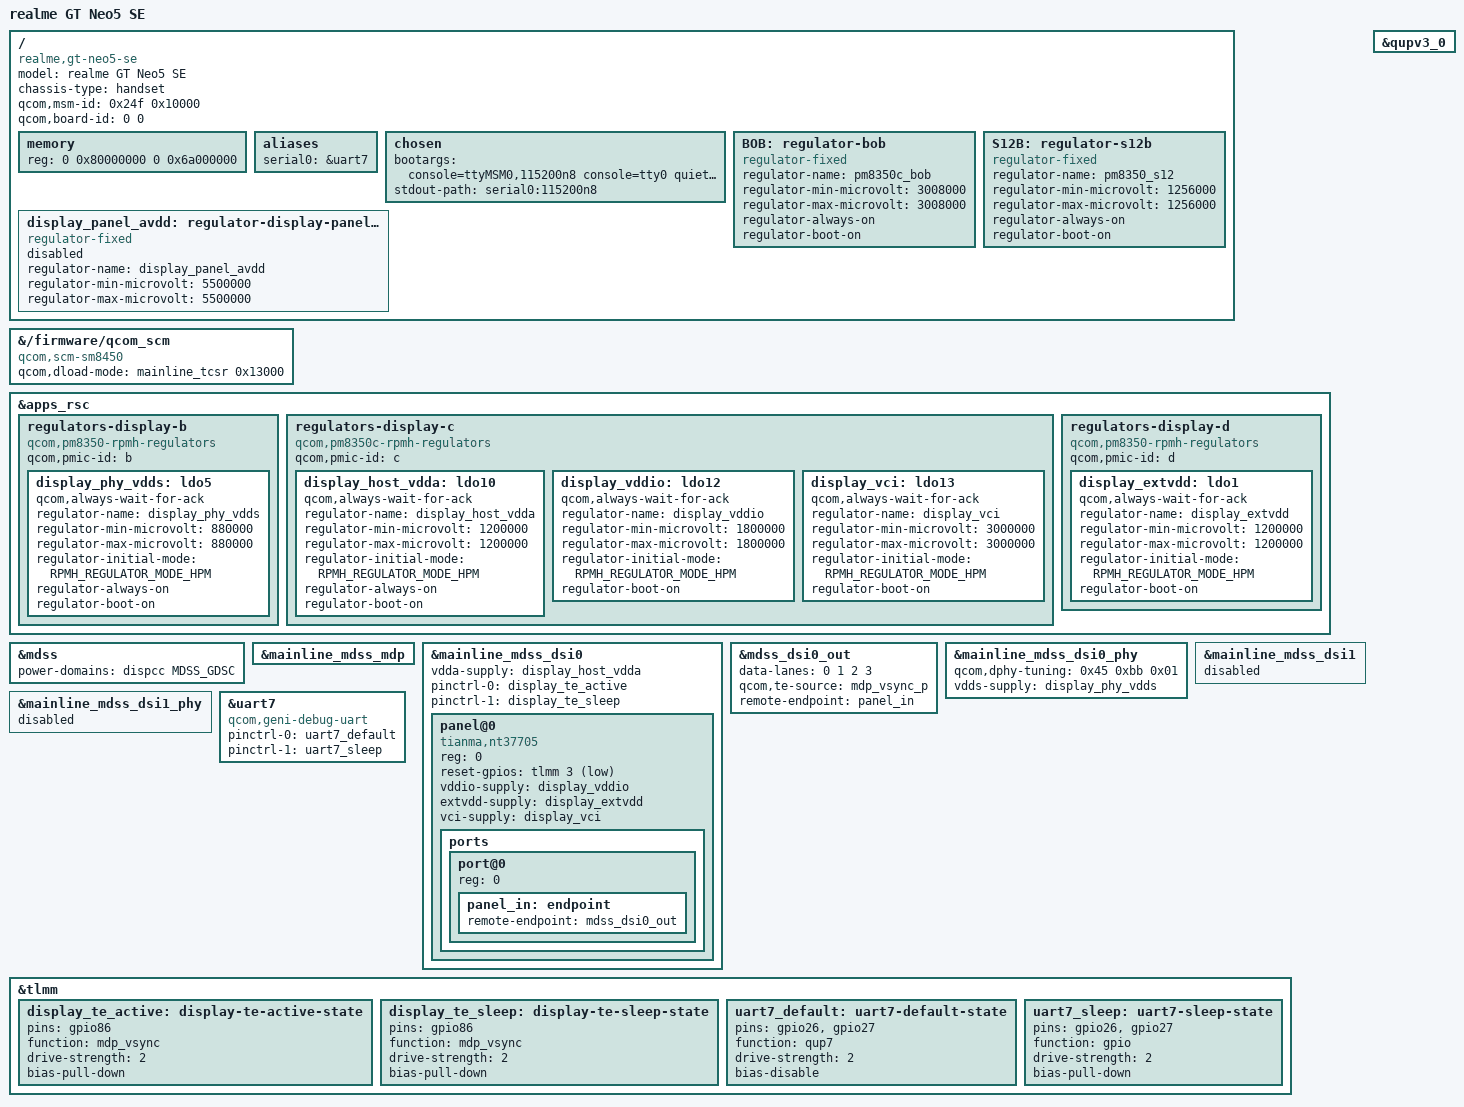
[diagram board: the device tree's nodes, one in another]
// SPDX-License-Identifier: BSD-3-Clause

/dts-v1/;

#include "sm7475.dtsi"
#include <dt-bindings/gpio/gpio.h>
#include <dt-bindings/regulator/qcom,rpmh-regulator.h>
/* Labels the bootloader needs to merge the factory dtbo overlays; see the file. */
#include "sm7475-realme-gt-neo5-se-abl-labels.dtsi"
/* Top-level nodes the stock base has and the bootloader may fix up; see the file. */
#include "sm7475-realme-gt-neo5-se-stock-nodes.dtsi"
/* Batch 1 of the /soc migration (SPMI/PMIC subsystem); see the file. */
#include "sm7475-realme-gt-neo5-se-soc-spmi.dtsi"
/* The UFS host and PHY; see the file. */
#include "sm7475-realme-gt-neo5-se-ufs.dtsi"
/* USB2 (DWC3 + HS PHY) for the gadget debug console; see the file. */
#include "sm7475-realme-gt-neo5-se-usb.dtsi"

/ {
	model = "realme GT Neo5 SE";
	/* "qcom,ukee" is what the stock base declares, and what the bootloader
	 * itself writes into the tree it hands the kernel.  Keep our own strings
	 * first, then add the platform ones, so base selection cannot skip us for
	 * carrying only an unknown board string. */
	compatible = "realme,gt-neo5-se", "qcom,sm7475",
		     "qcom,ukee-mtp", "qcom,ukee", "qcom,mtp";
	chassis-type = "handset";
	qcom,msm-id = <0x24f 0x10000>;
	/* The stock base declares <0 0> - an "any board" wildcard - and carries no
	 * pmic-id at all; pmic-id belongs on the dtbo entry, not on the base.
	 * Writing a specific board-id / pmic-id here makes base selection stricter
	 * than the stock image and can get our slot skipped. */
	qcom,board-id = <0 0>;

	/* Safe first-bank fallback from the installed device's RAM map.
	 * The bootloader may replace this with the full installed RAM banks.
	 */
	memory {
		reg = <0 0x80000000 0 0x6a000000>;
	};

	/* The factory dtbo extends /aliases, so it needs the stock label. */
	aliases: aliases {
		serial0 = &uart7;
	};

	/* The stock base's /chosen carries only a bootargs string and
	 * stdout-path; the bootloader adds kaslr-seed / linux,initrd-start /
	 * linux,initrd-end itself on every boot even though the stock blob has no
	 * spare room for them, so pre-creating them here is not needed.  The
	 * splash console driver registers the panel scanout buffer directly
	 * (see drivers/soc/qcom/sm7475-splashfb.c) and needs no framebuffer node.
	 */
	chosen: chosen {
		bootargs = "console=ttyMSM0,115200n8 console=tty0 quiet clk_ignore_unused regulator_ignore_unused";
		stdout-path = "serial0:115200n8";
	};

	/*
	 * Rails the factory dtbo consumes but this tree cannot drive yet.
	 *
	 * The dtbo's camera LDOs (fragment@82: gpio-regulator@0/@1) take their
	 * vin-supply from S12B (pm8350 S12) and BOB (pm8350c BOB), and its
	 * wcd938x codec takes cdc-vdd-mic-bias-supply from BOB.  Those labels
	 * used to sit on empty sink nodes in sm7475-realme-gt-neo5-se-abl-
	 * labels.dtsi, so the supplies resolved to a node with no driver and
	 * both LDOs sat in deferred probe forever:
	 *
	 *   deferred probe pending: platform: wait for supplier
	 *                           /abl_overlay_sink/abl-sym-1
	 *
	 * The dtbo only *consumes* these labels (it never merges content into
	 * them), so - exactly as with the UFS rails - they move onto real nodes
	 * here.  The rails are PMIC/RPMH regulators the bootloader leaves
	 * enabled (it boots from a rail-controlled UFS), so until the PMIC is
	 * described they are modelled as fixed always-on.
	 *
	 * reg-fixed-voltage rejects a node with min != max outright
	 * ("Fixed regulator specified with variable voltages", -EINVAL), so each
	 * rail gets a single level rather than the stock node's supported
	 * window: S12B takes the stock node's own qcom,init-voltage (0x132a40),
	 * BOB the bottom of its window because the stock node carries no plain
	 * init value for it.  The real level stays whatever the PMIC has it set
	 * to; the drivers only read it and enable the supply.
	 */
	BOB: regulator-bob {
		compatible = "regulator-fixed";
		regulator-name = "pm8350c_bob";
		regulator-min-microvolt = <3008000>;
		regulator-max-microvolt = <3008000>;
		regulator-always-on;
		regulator-boot-on;
	};

	S12B: regulator-s12b {
		compatible = "regulator-fixed";
		regulator-name = "pm8350_s12";
		regulator-min-microvolt = <1256000>;
		regulator-max-microvolt = <1256000>;
		regulator-always-on;
		regulator-boot-on;
	};

	/* The factory AVDD placeholder has no GPIO/pinctrl hookup on Senna.
	 * Preserve its diagnostic label without driving the unrelated GPIO186.
	 */
	display_panel_avdd: regulator-display-panel-avdd {
		compatible = "regulator-fixed";
		regulator-name = "display_panel_avdd";
		regulator-min-microvolt = <5500000>;
		regulator-max-microvolt = <5500000>;
		status = "disabled";
	};

};

/*
 * The copied stock phandle number is not valid after dtc reallocates phandles.
 * SCM must probe before the Qualcomm SMMU implementation can bind.
 */
&{/firmware/qcom_scm} {
	compatible = "qcom,scm-sm8450", "qcom,scm";
	qcom,dload-mode = <&mainline_tcsr 0x13000>;
	#reset-cells = <1>;
};

/* Stock display resources: ldob5, ldoc10/12/13 and ldod1. */
&apps_rsc {
	regulators-display-b {
		compatible = "qcom,pm8350-rpmh-regulators";
		qcom,pmic-id = "b";

		display_phy_vdds: ldo5 {
			qcom,always-wait-for-ack;
			regulator-name = "display_phy_vdds";
			regulator-min-microvolt = <880000>;
			regulator-max-microvolt = <880000>;
			regulator-initial-mode = <RPMH_REGULATOR_MODE_HPM>;
			/* Shared with the USB/UFS PHYs, still using fixed rails. */
			regulator-always-on;
			regulator-boot-on;
		};
	};

	regulators-display-c {
		compatible = "qcom,pm8350c-rpmh-regulators";
		qcom,pmic-id = "c";

		display_host_vdda: ldo10 {
			qcom,always-wait-for-ack;
			regulator-name = "display_host_vdda";
			regulator-min-microvolt = <1200000>;
			regulator-max-microvolt = <1200000>;
			regulator-initial-mode = <RPMH_REGULATOR_MODE_HPM>;
			/* The USB PHY also consumes PM8350C L10. */
			regulator-always-on;
			regulator-boot-on;
		};

		display_vddio: ldo12 {
			qcom,always-wait-for-ack;
			regulator-name = "display_vddio";
			regulator-min-microvolt = <1800000>;
			regulator-max-microvolt = <1800000>;
			regulator-initial-mode = <RPMH_REGULATOR_MODE_HPM>;
			regulator-boot-on;
		};

		display_vci: ldo13 {
			qcom,always-wait-for-ack;
			regulator-name = "display_vci";
			regulator-min-microvolt = <3000000>;
			regulator-max-microvolt = <3000000>;
			regulator-initial-mode = <RPMH_REGULATOR_MODE_HPM>;
			regulator-boot-on;
		};
	};

	regulators-display-d {
		/* PM8350B L1 uses the same PMIC5 NLDO programming as PM8350. */
		compatible = "qcom,pm8350-rpmh-regulators";
		qcom,pmic-id = "d";

		display_extvdd: ldo1 {
			qcom,always-wait-for-ack;
			regulator-name = "display_extvdd";
			regulator-min-microvolt = <1200000>;
			regulator-max-microvolt = <1200000>;
			regulator-initial-mode = <RPMH_REGULATOR_MODE_HPM>;
			regulator-boot-on;
		};
	};
};

&mdss {
	power-domains = <&dispcc MDSS_GDSC>;
	status = "okay";
};

&mainline_mdss_mdp {
	status = "okay";
};

&mainline_mdss_dsi0 {
	/* The stock DSI host rail is PM8350C L10 at 1.2 V (vdda-1p2). */
	vdda-supply = <&display_host_vdda>;
	pinctrl-0 = <&display_te_active>;
	pinctrl-1 = <&display_te_sleep>;
	pinctrl-names = "default", "sleep";
	status = "okay";

	panel@0 {
		compatible = "tianma,nt37705";
		reg = <0>;
		/* Map the driver's logical 0-1-0 sequence to the stock H-L-H pulse. */
		reset-gpios = <&tlmm 3 GPIO_ACTIVE_LOW>;
		vddio-supply = <&display_vddio>;
		extvdd-supply = <&display_extvdd>;
		vci-supply = <&display_vci>;

		ports {
			#address-cells = <1>;
			#size-cells = <0>;
			port@0 {
				reg = <0>;
				panel_in: endpoint {
					remote-endpoint = <&mdss_dsi0_out>;
				};
			};
		};
	};
};

&mdss_dsi0_out {
	data-lanes = <0 1 2 3>;
	qcom,te-source = "mdp_vsync_p";
	remote-endpoint = <&panel_in>;
};

&mainline_mdss_dsi0_phy {
	/* Stock Senna PHY v4.3.2 analog tuning (VREG0, HSTX, calibration). */
	qcom,dphy-tuning = <0x45 0xbb 0x01>;
	vdds-supply = <&display_phy_vdds>;
	status = "okay";
};

&mainline_mdss_dsi1 {
	status = "disabled";
};

&mainline_mdss_dsi1_phy {
	status = "disabled";
};
&qupv3_0 {
	status = "okay";
};

&uart7 {
	compatible = "qcom,geni-debug-uart", "qcom,msm-geni-console";
	pinctrl-0 = <&uart7_default>;
	pinctrl-1 = <&uart7_sleep>;
	pinctrl-names = "default", "sleep";
	status = "okay";
};

&tlmm {
	/* Stock Senna routes the panel TE line (GPIO86) to DPU vsync. */
	display_te_active: display-te-active-state {
		pins = "gpio86";
		function = "mdp_vsync";
		drive-strength = <2>;
		bias-pull-down;
	};

	display_te_sleep: display-te-sleep-state {
		pins = "gpio86";
		function = "mdp_vsync";
		drive-strength = <2>;
		bias-pull-down;
	};

	uart7_default: uart7-default-state {
		pins = "gpio26", "gpio27";
		function = "qup7";
		drive-strength = <2>;
		bias-disable;
	};

	uart7_sleep: uart7-sleep-state {
		pins = "gpio26", "gpio27";
		function = "gpio";
		drive-strength = <2>;
		bias-pull-down;
	};

};
